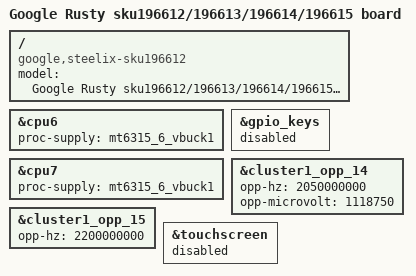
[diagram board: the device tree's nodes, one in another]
// SPDX-License-Identifier: (GPL-2.0 OR MIT)
/*
 * Copyright 2022 Google LLC
 */

/dts-v1/;
#include "mt8186-corsola-steelix.dtsi"
#include "mt6315.dtsi"

/ {
	model = "Google Rusty sku196612/196613/196614/196615 board";
	compatible = "google,steelix-sku196612", "google,steelix-sku196613",
		     "google,steelix-sku196614", "google,steelix-sku196615",
		     "google,steelix", "mediatek,mt8186";
};

&cpu6 {
	proc-supply = <&mt6315_6_vbuck1>;
};

&cpu7 {
	proc-supply = <&mt6315_6_vbuck1>;
};

&gpio_keys {
	status = "disabled";
};

&cluster1_opp_14 {
	opp-hz = /bits/ 64 <2050000000>;
	opp-microvolt = <1118750>;
};

&cluster1_opp_15 {
	opp-hz = /bits/ 64 <2200000000>;
};

&touchscreen {
	status = "disabled";
};
